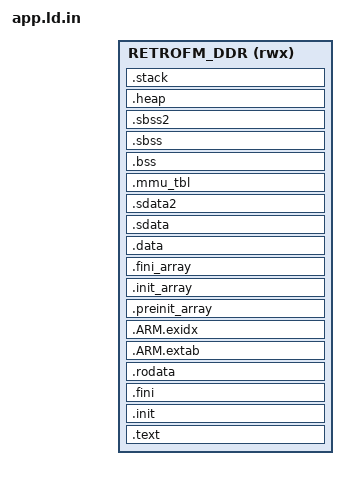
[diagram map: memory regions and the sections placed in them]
/* SPDX-License-Identifier: GPL-3.0-or-later */
/* Generated values come from the application-domain xparameters.h. */

_STACK_SIZE = DEFINED(_STACK_SIZE) ? _STACK_SIZE : 0x4000;
_HEAP_SIZE = DEFINED(_HEAP_SIZE) ? _HEAP_SIZE : 0x4000;
_ABORT_STACK_SIZE = DEFINED(_ABORT_STACK_SIZE) ? _ABORT_STACK_SIZE : 1024;
_SUPERVISOR_STACK_SIZE = DEFINED(_SUPERVISOR_STACK_SIZE) ?
                         _SUPERVISOR_STACK_SIZE : 2048;
_IRQ_STACK_SIZE = DEFINED(_IRQ_STACK_SIZE) ? _IRQ_STACK_SIZE : 2048;
_FIQ_STACK_SIZE = DEFINED(_FIQ_STACK_SIZE) ? _FIQ_STACK_SIZE : 1024;
_UNDEF_STACK_SIZE = DEFINED(_UNDEF_STACK_SIZE) ? _UNDEF_STACK_SIZE : 1024;

MEMORY
{
    RETROFM_DDR (rwx) : ORIGIN = @DDR_ORIGIN@, LENGTH = @DDR_LENGTH@
}

ENTRY(_vector_table)

SECTIONS
{
    .text : {
        . = ALIGN(2048);
        KEEP(*(.vectors))
        *(.boot)
        *(.text .text.* .gnu.linkonce.t.*)
        *(.plt .glue_7 .glue_7t .vfp11_veneer)
    } > RETROFM_DDR

    .init : { KEEP(*(.init)) } > RETROFM_DDR
    .fini : { KEEP(*(.fini)) } > RETROFM_DDR
    .rodata : { *(.rodata .rodata.* .gnu.linkonce.r.*) } > RETROFM_DDR
    .ARM.extab : { *(.ARM.extab* .gnu.linkonce.armextab.*) } > RETROFM_DDR
    .ARM.exidx : {
        __exidx_start = .;
        *(.ARM.exidx* .gnu.linkonce.armexidx.*)
        __exidx_end = .;
    } > RETROFM_DDR

    .preinit_array : {
        __preinit_array_start = .;
        KEEP(*(.preinit_array))
        __preinit_array_end = .;
    } > RETROFM_DDR
    .init_array : {
        __init_array_start = .;
        KEEP(*(SORT(.init_array.*)))
        KEEP(*(.init_array))
        __init_array_end = .;
    } > RETROFM_DDR
    .fini_array : {
        __fini_array_start = .;
        KEEP(*(SORT(.fini_array.*)))
        KEEP(*(.fini_array))
        __fini_array_end = .;
    } > RETROFM_DDR

    .data : {
        __data_start = .;
        *(.data .data.* .gnu.linkonce.d.*)
        *(.got .got.* .jcr)
        __data_end = .;
    } > RETROFM_DDR
    .sdata : {
        __sdata_start = .;
        *(.sdata .sdata.* .gnu.linkonce.s.*)
        __sdata_end = .;
    } > RETROFM_DDR
    .sdata2 : {
        __sdata2_start = .;
        *(.sdata2 .sdata2.* .gnu.linkonce.s2.*)
        __sdata2_end = .;
    } > RETROFM_DDR

    .mmu_tbl (ALIGN(16384)) : {
        __mmu_tbl_start = .;
        *(.mmu_tbl)
        __mmu_tbl_end = .;
    } > RETROFM_DDR

    .bss (NOLOAD) : {
        __bss_start = .;
        *(.bss .bss.* .gnu.linkonce.b.*)
        *(COMMON)
        __bss_end = .;
    } > RETROFM_DDR
    .sbss (NOLOAD) : {
        __sbss_start = .;
        *(.sbss .sbss.* .gnu.linkonce.sb.*)
        __sbss_end = .;
    } > RETROFM_DDR
    .sbss2 (NOLOAD) : {
        __sbss2_start = .;
        *(.sbss2 .sbss2.* .gnu.linkonce.sb2.*)
        __sbss2_end = .;
    } > RETROFM_DDR

    _SDA_BASE_ = __sdata_start + ((__sbss_end - __sdata_start) / 2);
    _SDA2_BASE_ = __sdata2_start + ((__sbss2_end - __sdata2_start) / 2);

    .heap (NOLOAD) : {
        . = ALIGN(16);
        _heap = .;
        HeapBase = .;
        _heap_start = .;
        . += _HEAP_SIZE;
        _heap_end = .;
        HeapLimit = .;
    } > RETROFM_DDR

    .stack (NOLOAD) : {
        . = ALIGN(16);
        _stack_end = .;
        . += _STACK_SIZE;
        . = ALIGN(16);
        _stack = .;
        __stack = .;
        _irq_stack_end = .;
        . += _IRQ_STACK_SIZE;
        __irq_stack = .;
        _supervisor_stack_end = .;
        . += _SUPERVISOR_STACK_SIZE;
        __supervisor_stack = .;
        _abort_stack_end = .;
        . += _ABORT_STACK_SIZE;
        __abort_stack = .;
        _fiq_stack_end = .;
        . += _FIQ_STACK_SIZE;
        __fiq_stack = .;
        _undef_stack_end = .;
        . += _UNDEF_STACK_SIZE;
        __undef_stack = .;
    } > RETROFM_DDR

    _end = .;
}
